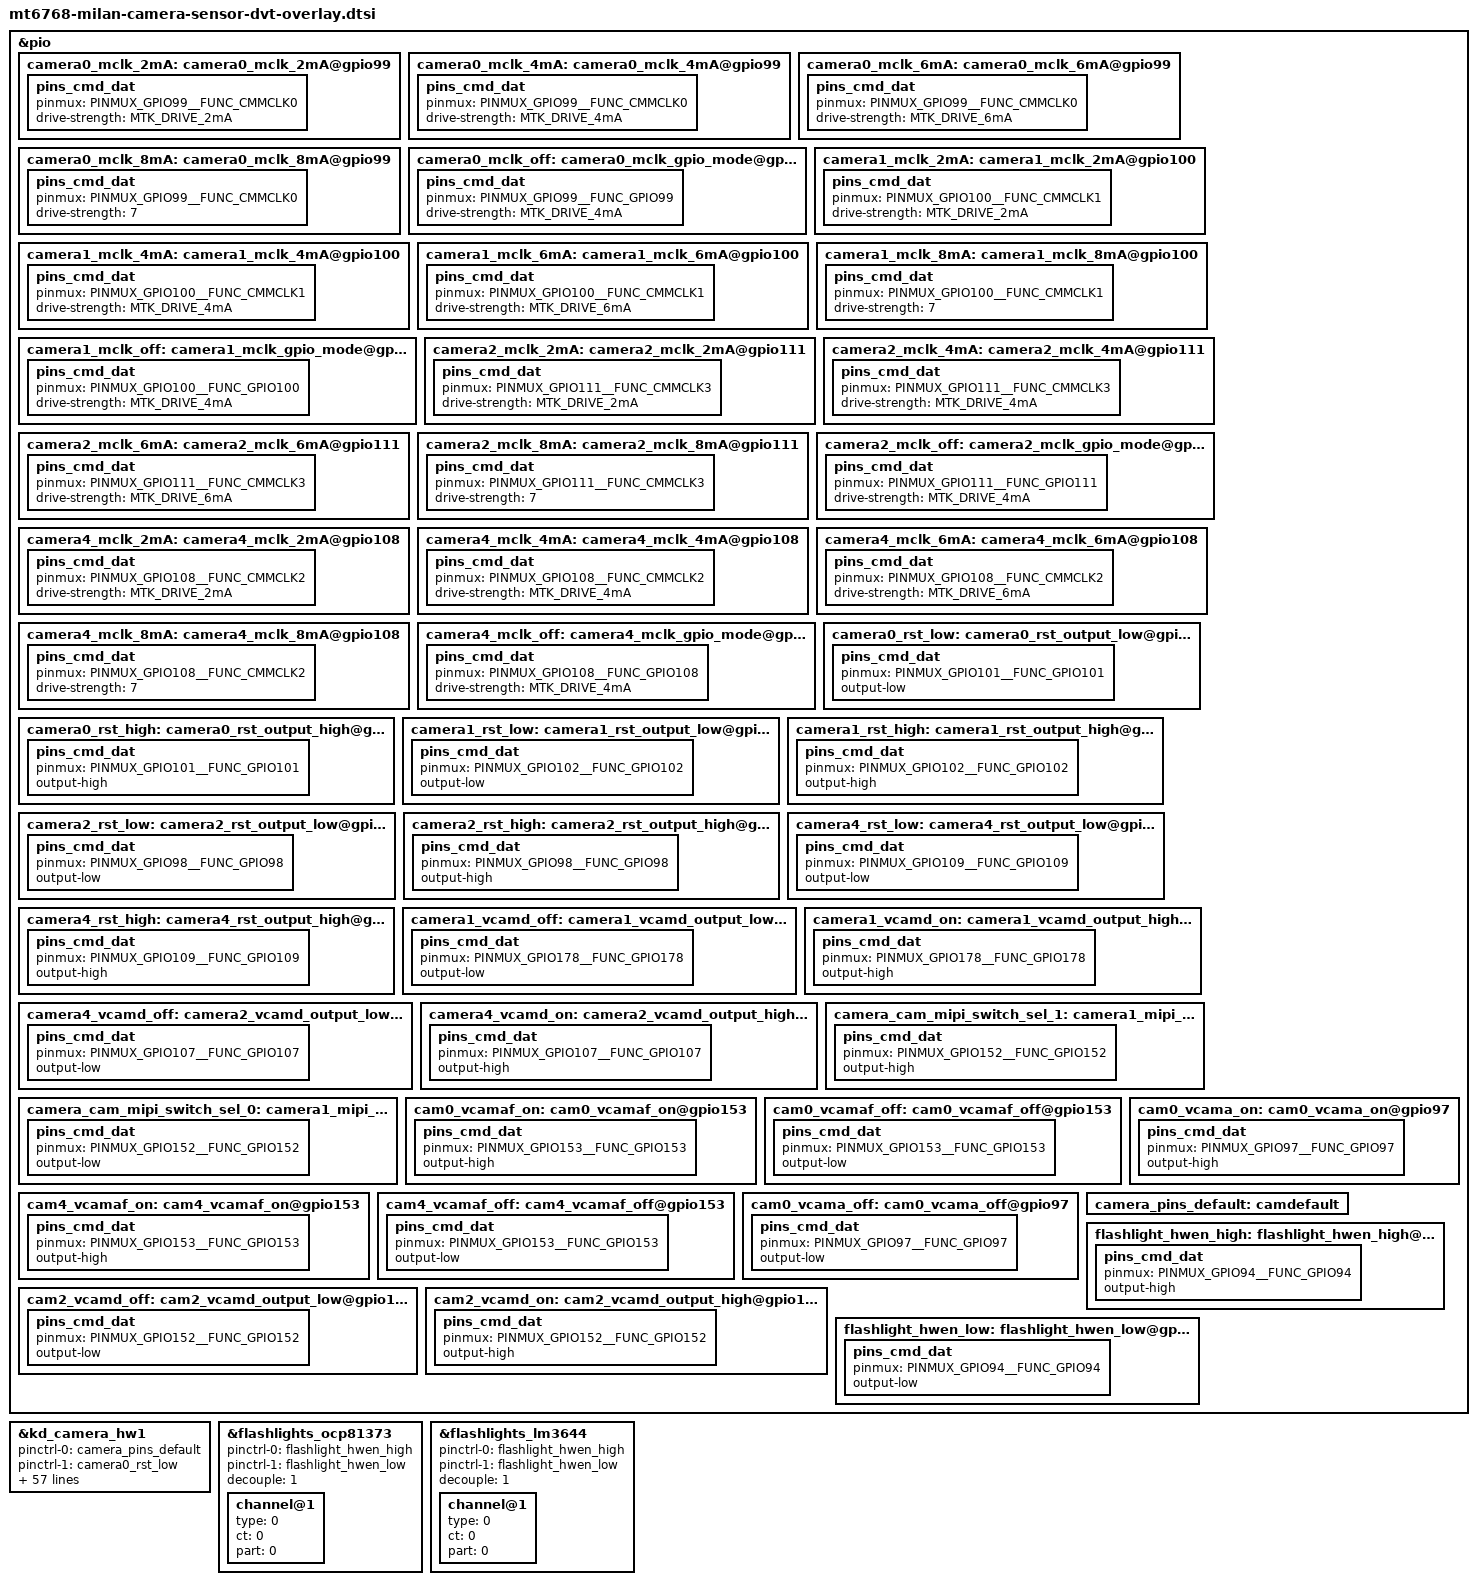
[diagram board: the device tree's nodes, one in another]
/*
 * Copyright (c) 2019 MediaTek Inc.
 *
 * This program is free software; you can redistribute it and/or modify
 * it under the terms of the GNU General Public License version 2 as
 * published by the Free Software Foundation.
 *
 * This program is distributed in the hope that it will be useful,
 * but WITHOUT ANY WARRANTY; without even the implied warranty of
 * MERCHANTABILITY or FITNESS FOR A PARTICULAR PURPOSE.  See the
 * GNU General Public License for more details.
 */
/* CAMERA GPIO standardization */
&pio {
	camera0_mclk_2mA: camera0_mclk_2mA@gpio99 {
		pins_cmd_dat {
			pinmux = <PINMUX_GPIO99__FUNC_CMMCLK0>;
			drive-strength = <MTK_DRIVE_2mA>;
		};
	};
	camera0_mclk_4mA: camera0_mclk_4mA@gpio99 {
		pins_cmd_dat {
			pinmux = <PINMUX_GPIO99__FUNC_CMMCLK0>;
			drive-strength = <MTK_DRIVE_4mA>;
		};
	};
	camera0_mclk_6mA: camera0_mclk_6mA@gpio99 {
		pins_cmd_dat {
			pinmux = <PINMUX_GPIO99__FUNC_CMMCLK0>;
			drive-strength = <MTK_DRIVE_6mA>;
		};
	};
	camera0_mclk_8mA: camera0_mclk_8mA@gpio99 {
		pins_cmd_dat {
			pinmux = <PINMUX_GPIO99__FUNC_CMMCLK0>;
			drive-strength = <7>;
		};
	};
	camera0_mclk_off: camera0_mclk_gpio_mode@gpio99 {
		pins_cmd_dat {
			pinmux = <PINMUX_GPIO99__FUNC_GPIO99>;
			drive-strength = <MTK_DRIVE_4mA>;
		};
	};
	camera1_mclk_2mA: camera1_mclk_2mA@gpio100 {
		pins_cmd_dat {
			pinmux = <PINMUX_GPIO100__FUNC_CMMCLK1>;
			drive-strength = <MTK_DRIVE_2mA>;
		};
	};
	camera1_mclk_4mA: camera1_mclk_4mA@gpio100 {
		pins_cmd_dat {
			pinmux = <PINMUX_GPIO100__FUNC_CMMCLK1>;
			drive-strength = <MTK_DRIVE_4mA>;
		};
	};
	camera1_mclk_6mA: camera1_mclk_6mA@gpio100 {
		pins_cmd_dat {
			pinmux = <PINMUX_GPIO100__FUNC_CMMCLK1>;
			drive-strength = <MTK_DRIVE_6mA>;
		};
	};
	camera1_mclk_8mA: camera1_mclk_8mA@gpio100 {
		pins_cmd_dat {
			pinmux = <PINMUX_GPIO100__FUNC_CMMCLK1>;
			drive-strength = <7>;
		};
	};
	camera1_mclk_off: camera1_mclk_gpio_mode@gpio100 {
		pins_cmd_dat {
			pinmux = <PINMUX_GPIO100__FUNC_GPIO100>;
			drive-strength = <MTK_DRIVE_4mA>;
		};
	};
	camera2_mclk_2mA: camera2_mclk_2mA@gpio111 {
		pins_cmd_dat {
			pinmux = <PINMUX_GPIO111__FUNC_CMMCLK3>;
			drive-strength = <MTK_DRIVE_2mA>;
		};
	};
	camera2_mclk_4mA: camera2_mclk_4mA@gpio111 {
		pins_cmd_dat {
			pinmux = <PINMUX_GPIO111__FUNC_CMMCLK3>;
			drive-strength = <MTK_DRIVE_4mA>;
		};
	};
	camera2_mclk_6mA: camera2_mclk_6mA@gpio111 {
		pins_cmd_dat {
			pinmux = <PINMUX_GPIO111__FUNC_CMMCLK3>;
			drive-strength = <MTK_DRIVE_6mA>;
		};
	};
	camera2_mclk_8mA: camera2_mclk_8mA@gpio111 {
		pins_cmd_dat {
			pinmux = <PINMUX_GPIO111__FUNC_CMMCLK3>;
			drive-strength = <7>;
		};
	};
	camera2_mclk_off: camera2_mclk_gpio_mode@gpio111 {
		pins_cmd_dat {
			pinmux = <PINMUX_GPIO111__FUNC_GPIO111>;
			drive-strength = <MTK_DRIVE_4mA>;
		};
	};
	camera4_mclk_2mA: camera4_mclk_2mA@gpio108 {
		pins_cmd_dat {
			pinmux = <PINMUX_GPIO108__FUNC_CMMCLK2>;
			drive-strength = <MTK_DRIVE_2mA>;
		};
	};
	camera4_mclk_4mA: camera4_mclk_4mA@gpio108 {
		pins_cmd_dat {
			pinmux = <PINMUX_GPIO108__FUNC_CMMCLK2>;
			drive-strength = <MTK_DRIVE_4mA>;
		};
	};
	camera4_mclk_6mA: camera4_mclk_6mA@gpio108 {
		pins_cmd_dat {
			pinmux = <PINMUX_GPIO108__FUNC_CMMCLK2>;
			drive-strength = <MTK_DRIVE_6mA>;
		};
	};
	camera4_mclk_8mA: camera4_mclk_8mA@gpio108 {
		pins_cmd_dat {
			pinmux = <PINMUX_GPIO108__FUNC_CMMCLK2>;
			drive-strength = <7>;
		};
	};
	camera4_mclk_off: camera4_mclk_gpio_mode@gpio108 {
		pins_cmd_dat {
			pinmux = <PINMUX_GPIO108__FUNC_GPIO108>;
			drive-strength = <MTK_DRIVE_4mA>;
		};
	};
	camera0_rst_low: camera0_rst_output_low@gpio101 {
		pins_cmd_dat {
			pinmux = <PINMUX_GPIO101__FUNC_GPIO101>;
			output-low;
		};
	};
	camera0_rst_high: camera0_rst_output_high@gpio101 {
		pins_cmd_dat {
			pinmux = <PINMUX_GPIO101__FUNC_GPIO101>;
			output-high;
		};
	};
	camera1_rst_low: camera1_rst_output_low@gpio102 {
		pins_cmd_dat {
			pinmux = <PINMUX_GPIO102__FUNC_GPIO102>;
			output-low;
		};
	};
	camera1_rst_high: camera1_rst_output_high@gpio102 {
		pins_cmd_dat {
			pinmux = <PINMUX_GPIO102__FUNC_GPIO102>;
			output-high;
		};
	};
	camera2_rst_low: camera2_rst_output_low@gpio98 {
		pins_cmd_dat {
			pinmux = <PINMUX_GPIO98__FUNC_GPIO98>;
			output-low;
		};
	};
	camera2_rst_high: camera2_rst_output_high@gpio98 {
		pins_cmd_dat {
			pinmux = <PINMUX_GPIO98__FUNC_GPIO98>;
			output-high;
		};
	};
	camera4_rst_low: camera4_rst_output_low@gpio109 {
		pins_cmd_dat {
			pinmux = <PINMUX_GPIO109__FUNC_GPIO109>;
			output-low;
		};
	};
	camera4_rst_high: camera4_rst_output_high@gpio109 {
		pins_cmd_dat {
			pinmux = <PINMUX_GPIO109__FUNC_GPIO109>;
			output-high;
		};
	};
	camera1_vcamd_off: camera1_vcamd_output_low@gpio178 {
		pins_cmd_dat {
			pinmux = <PINMUX_GPIO178__FUNC_GPIO178>;
			output-low;
		};
	};
	camera1_vcamd_on: camera1_vcamd_output_high@gpio178 {
		pins_cmd_dat {
			pinmux = <PINMUX_GPIO178__FUNC_GPIO178>;
			output-high;
		};
	};
	camera4_vcamd_off: camera2_vcamd_output_low@gpio107 {
		pins_cmd_dat {
			pinmux = <PINMUX_GPIO107__FUNC_GPIO107>;
			output-low;
		};
	};
	camera4_vcamd_on: camera2_vcamd_output_high@gpio107 {
		pins_cmd_dat {
			pinmux = <PINMUX_GPIO107__FUNC_GPIO107>;
			output-high;
		};
	};
	camera_cam_mipi_switch_sel_1: camera1_mipi_switch_output_high@gpio152 {
		pins_cmd_dat {
			pinmux = <PINMUX_GPIO152__FUNC_GPIO152>;
			output-high;
		};
	};
	camera_cam_mipi_switch_sel_0: camera1_mipi_switch_output_low@gpio152 {
		pins_cmd_dat {
			pinmux = <PINMUX_GPIO152__FUNC_GPIO152>;
			output-low;
		};
	};
	cam0_vcamaf_on: cam0_vcamaf_on@gpio153 {
		pins_cmd_dat {
			pinmux = <PINMUX_GPIO153__FUNC_GPIO153>;
			output-high;
		};
	};
	cam0_vcamaf_off: cam0_vcamaf_off@gpio153 {
		pins_cmd_dat {
			pinmux = <PINMUX_GPIO153__FUNC_GPIO153>;
			output-low;
		};
	};
	cam0_vcama_on: cam0_vcama_on@gpio97 {
		pins_cmd_dat {
			pinmux = <PINMUX_GPIO97__FUNC_GPIO97>;
			output-high;
		};
	};
	cam4_vcamaf_on: cam4_vcamaf_on@gpio153 {
		pins_cmd_dat {
			pinmux = <PINMUX_GPIO153__FUNC_GPIO153>;
			output-high;
		};
	};
	cam4_vcamaf_off: cam4_vcamaf_off@gpio153 {
		pins_cmd_dat {
			pinmux = <PINMUX_GPIO153__FUNC_GPIO153>;
			output-low;
		};
	};
	cam0_vcama_off: cam0_vcama_off@gpio97 {
		pins_cmd_dat {
			pinmux = <PINMUX_GPIO97__FUNC_GPIO97>;
			output-low;
		};
	};
	cam2_vcamd_off: cam2_vcamd_output_low@gpio152 {
		pins_cmd_dat {
			pinmux = <PINMUX_GPIO152__FUNC_GPIO152>;
			output-low;
		};
	};
	cam2_vcamd_on: cam2_vcamd_output_high@gpio152 {
		pins_cmd_dat {
			pinmux = <PINMUX_GPIO152__FUNC_GPIO152>;
			output-high;
		};
	};
	camera_pins_default: camdefault {
	};

};

&kd_camera_hw1 {
	pinctrl-names = "default",
			"cam0_rst0", "cam0_rst1",
			"cam1_rst0", "cam1_rst1",
			"cam2_rst0", "cam2_rst1",
			"cam4_rst0", "cam4_rst1",
			"cam1_vcamd_on",
			"cam1_vcamd_off",
			"cam4_vcamd_on",
			"cam4_vcamd_off",
			"cam0_mclk_off",
			"cam0_mclk_2mA", "cam0_mclk_4mA",
			"cam0_mclk_6mA", "cam0_mclk_8mA",
			"cam1_mclk_off",
			"cam1_mclk_2mA", "cam1_mclk_4mA",
			"cam1_mclk_6mA", "cam1_mclk_8mA",
			"cam2_mclk_off",
			"cam2_mclk_2mA", "cam2_mclk_4mA",
			"cam2_mclk_6mA", "cam2_mclk_8mA",
			"cam4_mclk_off",
			"cam4_mclk_2mA", "cam4_mclk_4mA",
			"cam4_mclk_6mA", "cam4_mclk_8mA",
			"cam_mipi_switch_sel_1", "cam_mipi_switch_sel_0",
			"cam0_vcamaf_on", "cam0_vcamaf_off",
			"cam0_vcama_on", "cam0_vcama_off",
			"cam2_vcamd_on",
			"cam2_vcamd_off","cam4_vcamaf_on", "cam4_vcamaf_off";

	pinctrl-0 = <&camera_pins_default>;
	pinctrl-1 = <&camera0_rst_low>;
	pinctrl-2 = <&camera0_rst_high>;
	pinctrl-3 = <&camera1_rst_low>;
	pinctrl-4 = <&camera1_rst_high>;
	pinctrl-5 = <&camera2_rst_low>;
	pinctrl-6 = <&camera2_rst_high>;
	pinctrl-7 = <&camera4_rst_low>;
	pinctrl-8 = <&camera4_rst_high>;
	pinctrl-9 = <&camera1_vcamd_on>;
	pinctrl-10 = <&camera1_vcamd_off>;
	pinctrl-11= <&camera4_vcamd_on>;
	pinctrl-12 = <&camera4_vcamd_off>;
	pinctrl-13 = <&camera0_mclk_off>;
	pinctrl-14 = <&camera0_mclk_2mA>;
	pinctrl-15 = <&camera0_mclk_4mA>;
	pinctrl-16 = <&camera0_mclk_6mA>;
	pinctrl-17 = <&camera0_mclk_8mA>;
	pinctrl-18 = <&camera1_mclk_off>;
	pinctrl-19 = <&camera1_mclk_2mA>;
	pinctrl-20 = <&camera1_mclk_4mA>;
	pinctrl-21 = <&camera1_mclk_6mA>;
	pinctrl-22 = <&camera1_mclk_8mA>;
	pinctrl-23 = <&camera2_mclk_off>;
	pinctrl-24 = <&camera2_mclk_2mA>;
	pinctrl-25 = <&camera2_mclk_4mA>;
	pinctrl-26 = <&camera2_mclk_6mA>;
	pinctrl-27 = <&camera2_mclk_8mA>;
	pinctrl-28 = <&camera4_mclk_off>;
	pinctrl-29 = <&camera4_mclk_2mA>;
	pinctrl-30 = <&camera4_mclk_4mA>;
	pinctrl-31 = <&camera4_mclk_6mA>;
	pinctrl-32 = <&camera4_mclk_8mA>;
	pinctrl-33 = <&camera_cam_mipi_switch_sel_1>;
	pinctrl-34 = <&camera_cam_mipi_switch_sel_0>;
	pinctrl-35 = <&cam0_vcamaf_on>;
	pinctrl-36 = <&cam0_vcamaf_off>;
	pinctrl-37 = <&cam0_vcama_on>;
	pinctrl-38 = <&cam0_vcama_off>;
	pinctrl-39 = <&cam2_vcamd_on>;
	pinctrl-40 = <&cam2_vcamd_off>;
	pinctrl-41 = <&cam4_vcamaf_on>;
	pinctrl-42 = <&cam4_vcamaf_off>;

	cam0_vcamd-supply = <&mt_pmic_vcamd_ldo_reg>;
	cam0_vcamio-supply = <&mt_pmic_vcamio_ldo_reg>;
	cam1_vcama-supply = <&mt_pmic_vcama2_ldo_reg>;
	cam2_vcama-supply = <&mt_pmic_vcama2_ldo_reg>;
	cam4_vcama-supply = <&mt_pmic_vcama1_ldo_reg>;
	cam1_vcamio-supply = <&mt_pmic_vcamio_ldo_reg>;
	cam2_vcamio-supply = <&mt_pmic_vcamio_ldo_reg>;
	cam4_vcamio-supply = <&mt_pmic_vcamio_ldo_reg>;
	cam1_vcamaf-supply = <&mt_pmic_vldo28_ldo_reg>;
	cam2_vcamaf-supply = <&mt_pmic_vldo28_ldo_reg>;

	cam0_enable_sensor = "mot_milan_s5kjn1_mipi_raw";
	cam1_enable_sensor = "mot_milan_ov16a1q_mipi_raw";
	cam2_enable_sensor = "mot_milan_gc02m1_mipi_raw";
	cam4_enable_sensor = "mot_milan_s5k4h7_mipi_raw";
	cust-sensor = "mot_milan_s5kjn1_mipi_raw mot_milan_ov16a1q_mipi_raw mot_milan_gc02m1_mipi_raw mot_milan_s5k4h7_mipi_raw";

	status = "okay";

};
/* CAMERA GPIO end */

/* flashlight gpio start*/
&pio {
	flashlight_hwen_high: flashlight_hwen_high@gpio94 {
		pins_cmd_dat {
			pinmux = <PINMUX_GPIO94__FUNC_GPIO94>;
			output-high;
		};
	};

	flashlight_hwen_low: flashlight_hwen_low@gpio94 {
		pins_cmd_dat {
			pinmux = <PINMUX_GPIO94__FUNC_GPIO94>;
			output-low;
		};
	};
};

&flashlights_ocp81373 {
	pinctrl-names = "flashlight_hwen_high",
			"flashlight_hwen_low";
	pinctrl-0 = <&flashlight_hwen_high>;
	pinctrl-1 = <&flashlight_hwen_low>;

	decouple = <1>;
	channel@1 {
		type = <0>;
		ct = <0>;
		part = <0>;
	};
};

&flashlights_lm3644 {
	pinctrl-names = "flashlight_hwen_high",
			"flashlight_hwen_low";
	pinctrl-0 = <&flashlight_hwen_high>;
	pinctrl-1 = <&flashlight_hwen_low>;

	decouple = <1>;
	channel@1 {
		type = <0>;
		ct = <0>;
		part = <0>;
	};
};
/* flashlight gpio end*/
